# KM1M7CF15 register map
Vendor: Nuvoton Technology Corporation Japan; Series: KM1M7CF; File version: 1.0.3
CPU: CM7 r1p2, little endian, MPU, FPU, double-precision FPU, I-cache, D-cache, ITCM, DTCM, 4 interrupt priority bits
Registers are 32-bit, read-write, no defined reset value unless marked. A register's access mark holds for its fields unless they carry their own. Offsets are from the block's base; [hi:lo] are bit positions; 'fields as' and 'values as' point back to an identical list.

## SIF01 — Serial Interface 0-1
Base 0x40050000
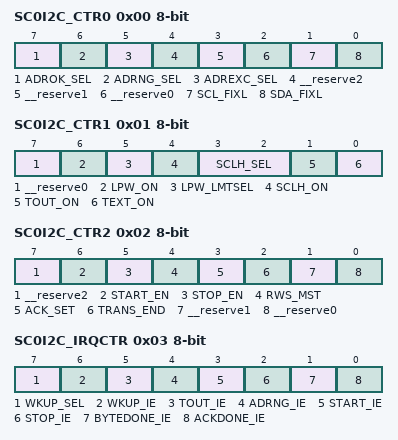
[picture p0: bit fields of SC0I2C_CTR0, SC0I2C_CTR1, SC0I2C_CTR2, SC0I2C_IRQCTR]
0x00 SC0I2C_CTR0 8-bit access per field — IIC Co0trol Register 0
  [7] ADROK_SEL rw — Slave address receive mode selection [IIC] (*1)(*3)
  [6] ADRNG_SEL rw — Slave address receive mode selection [IIC] (*1)(*3)
  [5] ADREXC_SEL rw — Extension code matching operation select [IIC] (*1)(*2)(*3)
  [4] __reserve2 ro — "0" is always read out.
  [3] __reserve1 rw — This bit must be set to "0".
  [2] __reserve0 ro — "0" is always read out.
  [1] SCL_FIXL rw — SCL port LOW level output [IIC] (*3)
  [0] SDA_FIXL rw — SDA port LOW level output [IIC] (*3)
0x01 SC0I2C_CTR1 8-bit access per field — IIC Co0trol Register 1
  [7] __reserve0 ro — "0" is always read out.
  [6] LPW_ON rw — Bus stop detection enable [IIC] (*1)
  [5] LPW_LMTSEL rw — Bus stop detection period [IIC] (*1)
  [4] SCLH_ON rw — Clock "High-level" period (THIGH) detection enable [IIC] (*1)
  [3:2] SCLH_SEL rw — Clock "High-level" period detection time [IIC] (*1)
  [1] TOUT_ON rw — Clock "Low-level" period (TTIMEOUT) detection enable [IIC] (*1)
  [0] TEXT_ON rw — TLOW:MEXT / TLOW:SEXT detection enable [IIC] (*1)
0x02 SC0I2C_CTR2 8-bit access per field — IIC Co0trol Register 2
  [7] __reserve2 ro — "0" is always read out.
  [6] START_EN rw — Start condition generation selection [IIC] (*1)(*4)
  [5] STOP_EN rw — Stop condition generation selection [IIC Master communication] (*2)(*4)
  [4] RWS_MST rw — Read/Write mode selection at Master [IIC] (*3)(*4)
  [3] ACK_SET rw — Transmission ACK bit selection [IIC] (*4)
  [2] TRANS_END rw — Communication end setting (*4)
  [1] __reserve1 ro — "0" is always read out.
  [0] __reserve0 ro — "0" is always read out.
0x03 SC0I2C_IRQCTR 8-bit — IIC I0terrupt Control Register
  [7] WKUP_SEL — Interrupt source selection for exiting CPU standby mode [IIC] (*5)
  [6] WKUP_IE — Enable CPU WAKEUP interrupt factor [IIC] (*1)(*5)
  [5] TOUT_IE — Enable Time-out interrupt factor [IIC] (*5)
  [4] ADRNG_IE — Enable Slave address mismatch interrupt factor [IIC] (*5)
  [3] START_IE — Enable Start condition detection interrupt factor [IIC] (*5)
  [2] STOP_IE — Enable Stop condition interrupt factor [IIC] (*5)
  [1] BYTEDONE_IE — Enable Byte data communication completion interrupt factor [IIC] (*2)(*3)(*5)
  [0] ACKDONE_IE — Enable ACK communication completion interrupt factor [IIC] (*4)(*5)
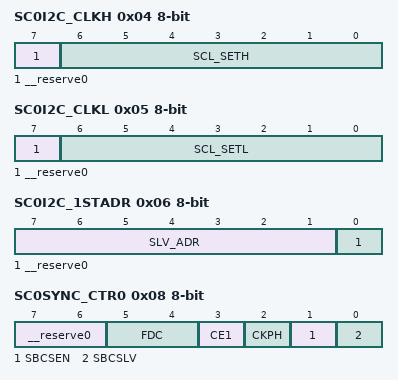
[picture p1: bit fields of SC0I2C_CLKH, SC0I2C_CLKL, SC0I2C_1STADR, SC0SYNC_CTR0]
0x04 SC0I2C_CLKH 8-bit access per field — IIC Clock High Level Freque0cy Setting Register
  [7] __reserve0 ro — "0" is always read out.
  [6:0] SCL_SETH rw — High level period of transfer clock at master communication [IIC] (*1)(*2)(*3)
0x05 SC0I2C_CLKL 8-bit access per field — IIC Clock Low Level Freque0cy Setting Register
  [7] __reserve0 ro — "0" is always read out.
  [6:0] SCL_SETL rw — Low level period of transfer clock at master communication [IIC] (*1)(*2)(*3)
0x06 SC0I2C_1STADR 8-bit access per field — IIC Slave Address Setti0g Register
  [7:1] SLV_ADR rw — Set the slave address. [IIC] (*1)(*2)
  [0] __reserve0 ro — "0" is always read out.
0x07 SC0I2C_TCLKOC 8-bit — IIC Timeout Clock Compare Register
  [7:0] TCLKOC — Time-out clock source division counter compare setting [IIC] (*1)(*2)
0x08 SC0SYNC_CTR0 8-bit access per field — Clock-Sy0chronous Control Register
  [7:6] __reserve0 ro — "0" is always read out.
  [5:4] FDC rw — Output level selection after the final bit transmit (SBOn pin) [Clock-Synchronous]
  [3] CE1 rw — Clock polarity selection (SCLn) [Clock-Synchronous]
  [2] CKPH rw — Clock Source Edge Selection [Clock-Synchronous]
  [1] SBCSEN rw — SBCSn function selection [Clock-Synchronous]
  [0] SBCSLV rw — SBCSn polarity selection [Clock-Synchronous]
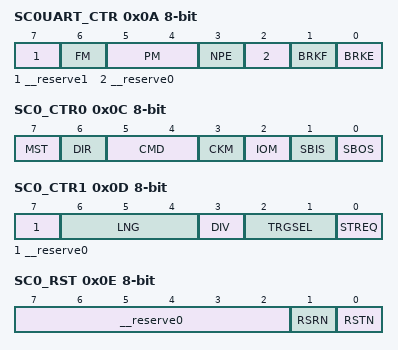
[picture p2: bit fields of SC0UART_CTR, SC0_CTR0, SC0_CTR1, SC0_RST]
0x0A SC0UART_CTR 8-bit access per field — UART Co0trol Register
  [7] __reserve1 ro — "0" is always read out.
  [6] FM rw — The number of character bit and stop bit selection [UART]
  [5:4] PM rw — Parity bit function selection [UART]
  [3] NPE rw — Parity bit selection [UART]
  [2] __reserve0 ro — "0" is always read out.
  [1] BRKF ro — Break reception detection [UART]
  [0] BRKE rw — Break transmission control [UART]
0x0C SC0_CTR0 8-bit — Serial 0 control register 0
  [7] MST — [Clock-Synchronous]
  [6] DIR — Transfer first bit selection
  [5:4] CMD — Communication mode selection (*1)
  [3] CKM — [Clock-Synchronous] Division selection of transfer clock
  [2] IOM — Data input pin selection (*2)
  [1] SBIS — SBIn/SBOn(SDAn) pin input control (*2)
  [0] SBOS — SBOn(SDAn) pin output control (*2)
0x0D SC0_CTR1 8-bit access per field — Serial 0 control register 1
  [7] __reserve0 ro — "0" is always read out.
  [6:4] LNG rw — Transfer bit count settings [Clock-Synchronous/UART]
  [3] DIV rw — Division value selection of transfer clock (*3)
  [2:1] TRGSEL rw — Selection of communication start factor(*1)
  [0] STREQ rw — Communication start trigger by software (*1)(*2)
0x0E SC0_RST 8-bit access per field — Serial 0 Reset Register
  [7:2] __reserve0 ro — "00" is always read out.
  [1] RSRN rw — [Clock-Synchronous]
  [0] RSTN rw — [Clock-Synchronous / IIC]
0x10 SC0RB 8-bit ro — Serial 0 Reception Data Buffer Register
  [7:0] RB — Reception data is read out.
0x12 SC0TB 8-bit — Serial 0 Transmission Data Buffer Register
  [7:0] TB — Set the transmission data or the dummy data.
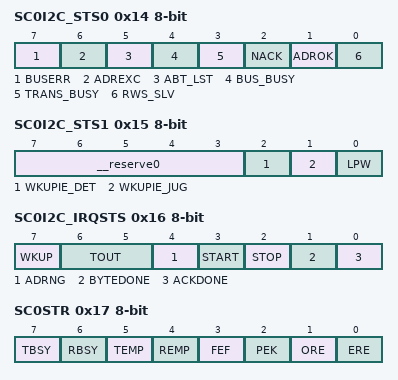
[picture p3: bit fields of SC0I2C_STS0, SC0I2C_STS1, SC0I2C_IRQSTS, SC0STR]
0x14 SC0I2C_STS0 8-bit access per field — IIC Status Register 0
  [7] BUSERR rw — Bus error detection [IIC] (*1)
  [6] ADREXC ro — Extension code receive detection [IIC]
  [5] ABT_LST rw — Arbitration lost detection [IIC] (*1)
  [4] BUS_BUSY ro — Bus busy state detection [IIC] (*2)
  [3] TRANS_BUSY ro — Communication busy state detection [IIC] (*3)
  [2] NACK ro — NACK detection [IIC]
  [1] ADROK ro — Slave address matching detection [IIC]
  [0] RWS_SLV ro — Read/ Write mode determination at Master/Slave communication [IIC] (*4)
0x15 SC0I2C_STS1 8-bit ro — IIC Status Register 1
  [7:3] __reserve0 — "0" is always read out.
  [2] WKUPIE_DET — CPU WAKEUP interrupt status [IIC]
  [1] WKUPIE_JUG — WKUP interrupt judgement [IIC]
  [0] LPW — Bus stop detection [IIC]
0x16 SC0I2C_IRQSTS 8-bit access per field — IIC I0terrupt Status Register
  [7] WKUP rw — IIC standby status exit detection [IIC] (*1)(*2)
  [6:5] TOUT ro — Time-out detection [IIC] (*2)
  [4] ADRNG rw — Slave address mismatch detection [IIC] (*1)(*2)
  [3] START rw — Start condition detection [IIC] (*1)(*2)(*3)
  [2] STOP rw — Stop condition detection [IIC] (*1)(*2)
  [1] BYTEDONE rw — Byte data communication completion detection [IIC] (*1)(*2)
  [0] ACKDONE rw — ACK communication completion detection (*1) [IIC] (*1)(*2)
0x17 SC0STR 8-bit access per field — Clock-Sy0chronous/UART Status Register
  [7] TBSY ro — Transmission busy detection [Clock-Synchronous/UART]
  [6] RBSY ro — Reception busy detection [Clock-Synchronous/UART]
  [5] TEMP ro — Transmission buffer empty [Clock-Synchronous/UART]
  [4] REMP ro — Reception buffer empty [Clock-Synchronous/UART]
  [3] FEF rw — Framing error detection [UART](*1)
  [2] PEK rw — Parity error detection [UART](*1)
  [1] ORE rw — Overrun error detection [Clock-Synchronous/UART](*1)
  [0] ERE ro — Reception error detection [Clock-Synchronous/UART]
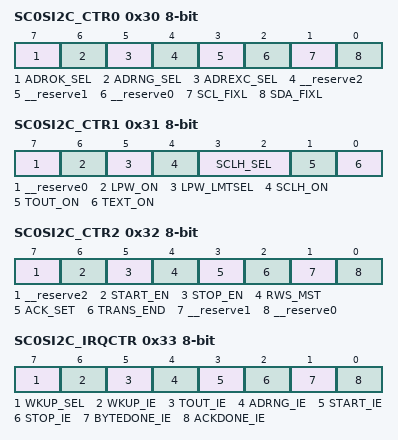
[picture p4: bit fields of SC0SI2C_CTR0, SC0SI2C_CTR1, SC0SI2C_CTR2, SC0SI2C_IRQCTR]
0x30 SC0SI2C_CTR0 8-bit wo — IIC Co0trol Set Register 0
  [7] ADROK_SEL — Set SCnI2C_CTR0.ADROK_SEL bit to "1"
  [6] ADRNG_SEL — Set SCnI2C_CTR0.ADRNG_SEL bit to "1"
  [5] ADREXC_SEL — Set SCnI2C_CTR0.ADREXC_SEL bit to "1"
  [4] __reserve2 — This bit must be set to "0".
  [3] __reserve1 — This bit must be set to "0".
  [2] __reserve0 — This bit must be set to "0".
  [1] SCL_FIXL — Set SCnI2C_CTR0.SCL_FIXL bit to "1"
  [0] SDA_FIXL — Set SCnI2C_CTR0.SDA_FIXL bit to "1"
0x31 SC0SI2C_CTR1 8-bit wo — IIC Co0trol Set Register 1
  [7] __reserve0 — This bit must be set to "0".
  [6] LPW_ON — Set SCnI2C_CTR1.LPW_ONL bit to "1"
  [5] LPW_LMTSEL — Set SCnI2C_CTR1.LPW_LMTSEL bit to "1"
  [4] SCLH_ON — Set SCnI2C_CTR1.SCLH_ON bit to "1"
  [3:2] SCLH_SEL — Set SCnI2C_CTR1.SCLH_SEL bit to "1"
  [1] TOUT_ON — Set SCnI2C_CTR1.TOUT_ON bit to "1"
  [0] TEXT_ON — Set SCnI2C_CTR1.TEXT_ON bit to "1"
0x32 SC0SI2C_CTR2 8-bit wo — IIC Co0trol Set Register 2
  [7] __reserve2 — This bit must be set to "0".
  [6] START_EN — Set SCnI2C_CTR2.START_EN bit to "1".
  [5] STOP_EN — Set SCnI2C_CTR2.STOP_EN bit to "1".
  [4] RWS_MST — Set SCnI2C_CTR2.RWS_MST bit to "1".
  [3] ACK_SET — Set SCnI2C_CTR2.ACK_SET bit to "1".
  [2] TRANS_END — Set SCnI2C_CTR2.TRANS_END bit to "1".
  [1] __reserve1 — This bit must be set to "0".
  [0] __reserve0 — This bit must be set to "0".
0x33 SC0SI2C_IRQCTR 8-bit wo — IIC I0terrupt Control Set Register
  [7] WKUP_SEL — Set SCnI2C_IRQCTR.WKUP_SEL bit to "1".
  [6] WKUP_IE — Set SCnI2C_IRQCTR.WKUP_IE bit to "1".
  [5] TOUT_IE — Set SCnI2C_IRQCTR.TOUT_IE bit to "1".
  [4] ADRNG_IE — Set SCnI2C_IRQCTR.ADRNG_IE bit to "1".
  [3] START_IE — Set SCnI2C_IRQCTR.START_IE bit to "1".
  [2] STOP_IE — Set SCnI2C_IRQCTR.STOP_IE bit to "1".
  [1] BYTEDONE_IE — Set SCnI2C_IRQCTR.BYTEDONE_IE bit to "1".
  [0] ACKDONE_IE — Set SCnI2C_IRQCTR.ACKDONE_IE bit to "1".
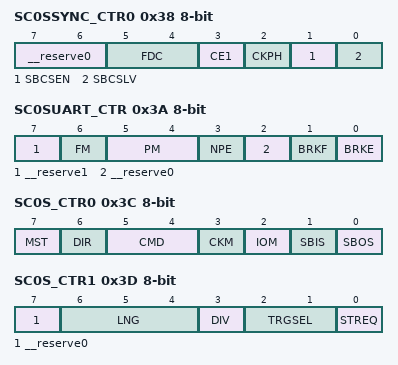
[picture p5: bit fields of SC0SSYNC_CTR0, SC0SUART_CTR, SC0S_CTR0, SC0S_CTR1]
0x38 SC0SSYNC_CTR0 8-bit wo — Clock-Sy0chronous Control Set Register
  [7:6] __reserve0 — This bit must be set to "0".
  [5:4] FDC — This bit must be set to "00".
  [3] CE1 — Set SCnSYNC_CTR0.CE1 bit to "1".
  [2] CKPH — Set SCnSYNC_CTR0.CKPH bit to "1".
  [1] SBCSEN — Set SCnSYNC_CTR0.SBCSEN bit to "1".
  [0] SBCSLV — Set SCnSYNC_CTR0.SBCSLV bit to "1".
0x3A SC0SUART_CTR 8-bit wo — UART Co0trol Set Register
  [7] __reserve1 — This bit must be set to "0".
  [6] FM — Set SCnUART_CTR.FM bit to "1"
  [5:4] PM — Set SCnUART_CTR.PM bit to "1"
  [3] NPE — Set SCnUART_CTR.NPE bit to "1"
  [2] __reserve0 — This bit must be set to "0".
  [1] BRKF — This bit must be set to "0".
  [0] BRKE — Set SCnUART_CTR.BRKE bit to "1"
0x3C SC0S_CTR0 8-bit wo — Serial 0 Control Set Register 0
  [7] MST — Set SCn_CTR0.MST bit to "1".
  [6] DIR — Set SCn_CTR0.DIR bit to "1".
  [5:4] CMD — This bit must be set to "00".
  [3] CKM — Set SCn_CTR0.CKM bit to "1".
  [2] IOM — Set SCn_CTR0.IOM bit to "1".
  [1] SBIS — Set SCn_CTR0.SBIS bit to "1".
  [0] SBOS — Set SCn_CTR0.SBOS bit to "1".
0x3D SC0S_CTR1 8-bit wo — Serial 0 Control Set Register 1
  [7] __reserve0 — This bit must be set to "0".
  [6:4] LNG — This bit must be set to "000".
  [3] DIV — Set SCn_CTR1.DIV bit to "1".
  [2:1] TRGSEL — This bit must be set to "00".
  [0] STREQ — Communication start trigger by software (*1)(*2)
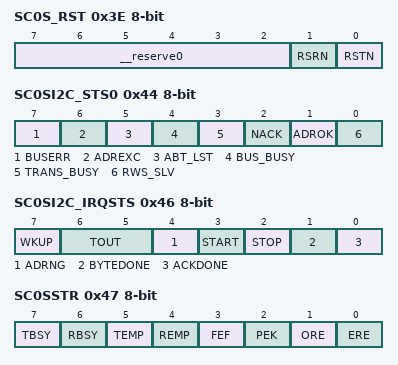
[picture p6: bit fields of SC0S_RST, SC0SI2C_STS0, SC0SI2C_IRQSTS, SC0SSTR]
0x3E SC0S_RST 8-bit wo — Serial 0 Reset Set Register
  [7:2] __reserve0 — This bit must be set to "00".
  [1] RSRN — Set SCn_RST.RSRN bit to "1"
  [0] RSTN — Set SCn_RST.RSTN bit to "1"
0x44 SC0SI2C_STS0 8-bit wo — IIC Status Set Register 0
  [7] BUSERR — Clear SCnI2C_STS0.BUSERR bit to "0".
  [6] ADREXC — This bit must be set to "0".
  [5] ABT_LST — Clear SCnI2C_STS0.ABT_LST bit to "0".
  [4] BUS_BUSY — This bit must be set to "0".
  [3] TRANS_BUSY — This bit must be set to "0".
  [2] NACK — This bit must be set to "0".
  [1] ADROK — This bit must be set to "0".
  [0] RWS_SLV — This bit must be set to "0".
0x46 SC0SI2C_IRQSTS 8-bit wo — IIC I0terrupt Clear Status Register
  [7] WKUP — Clear SCnI2C_IRQSTS.WKUP bit to "0".
  [6:5] TOUT — This bit must be set to "00".
  [4] ADRNG — Clear SCnI2C_IRQSTS.ADRNG bit to "0".
  [3] START — Clear C7I2C_IRQSTS.START bit to "0".
  [2] STOP — Clear SCnI2C_IRQSTS.STOP bit to "0".
  [1] BYTEDONE — Clear SCnI2C_IRQSTS.BYREDONE bit to "0".
  [0] ACKDONE — Clear SCnI2C_IRQSTS.ACKDONE bit to "0".
0x47 SC0SSTR 8-bit wo — Clock-Sy0chronous/UART Status Set Register
  [7] TBSY — This bit must be set to "0".
  [6] RBSY — This bit must be set to "0".
  [5] TEMP — This bit must be set to "0".
  [4] REMP — This bit must be set to "0".
  [3] FEF — Clear SCnSTR.FEF bit to "0". (*1)
  [2] PEK — Clear SCnSTR.PEK bit to "0". (*1)
  [1] ORE — Clear SCnSTR.ORE bit to "0". (*1)
  [0] ERE — This bit must be set to "0".
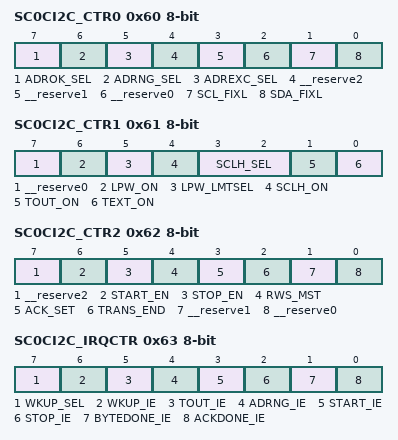
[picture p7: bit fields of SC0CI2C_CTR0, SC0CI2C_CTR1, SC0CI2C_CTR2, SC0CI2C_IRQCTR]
0x60 SC0CI2C_CTR0 8-bit wo — IIC Co0trol Clear Register 0
  [7] ADROK_SEL — Clear SCnI2C_CTR0.ADROK_SEL bit to "0"
  [6] ADRNG_SEL — Clear SCnI2C_CTR0.ADRNG_SEL bit to "0"
  [5] ADREXC_SEL — Clear SCnI2C_CTR0.ADREXC_SEL bit to "0"
  [4] __reserve2 — This bit must be set to "0".
  [3] __reserve1 — This bit must be set to "0".
  [2] __reserve0 — This bit must be set to "0".
  [1] SCL_FIXL — Clear SCnI2C_CTR0.SCL_FIXL bit to "0"
  [0] SDA_FIXL — Clear SCnI2C_CTR0.SDA_FIXL bit to "0"
0x61 SC0CI2C_CTR1 8-bit wo — IIC Co0trol Clear Register 1
  [7] __reserve0 — This bit must be set to "0".
  [6] LPW_ON — Clear SCnI2C_CTR1.LPW_ONL bit to "0"
  [5] LPW_LMTSEL — Clear SCnI2C_CTR1.LPW_LMTSEL bit to "0".
  [4] SCLH_ON — Clear SCnI2C_CTR1.SCLH_ON bit to "0".
  [3:2] SCLH_SEL — Clear SCnI2C_CTR1.SCLH_SEL bit to "0".
  [1] TOUT_ON — Clear SCnI2C_CTR1.TOUT_ON bit to "0".
  [0] TEXT_ON — Clear SCnI2C_CTR1.TEXT_ON bit to "0".
0x62 SC0CI2C_CTR2 8-bit wo — IIC Co0trol Clear Register 2
  [7] __reserve2 — This bit must be set to "0".
  [6] START_EN — Set SCnI2C_CTR2.START_EN bit to "0".
  [5] STOP_EN — Set SCnI2C_CTR2.STOP_EN bit to "0".
  [4] RWS_MST — Set SCnI2C_CTR2.RWS_MST bit to "0".
  [3] ACK_SET — Set SCnI2C_CTR2.ACK_SET bit to "0".
  [2] TRANS_END — Set SCnI2C_CTR2.TRANS_END bit to "0".
  [1] __reserve1 — This bit must be set to "0".
  [0] __reserve0 — This bit must be set to "0".
0x63 SC0CI2C_IRQCTR 8-bit wo — IIC I0terrupt Control Clear Register
  [7] WKUP_SEL — Clear SCnI2C_IRQCTR.WKUP_SEL bit to "0".
  [6] WKUP_IE — Clear SCnI2C_IRQCTR.WKUP_IE bit to "0".
  [5] TOUT_IE — Clear SCnI2C_IRQCTR.TOUT_IE bit to "0".
  [4] ADRNG_IE — Clear SCnI2C_IRQCTR.ADRNG_IE bit to "0".
  [3] START_IE — Clear SCnI2C_IRQCTR.START_IE bit to "0".
  [2] STOP_IE — Clear SCnI2C_IRQCTR.STOP_IE bit to "0".
  [1] BYTEDONE_IE — Clear SCnI2C_IRQCTR.BYTEDONE_IE bit to "0".
  [0] ACKDONE_IE — Clear SCnI2C_IRQCTR.ACKDONE_IE bit to "0".
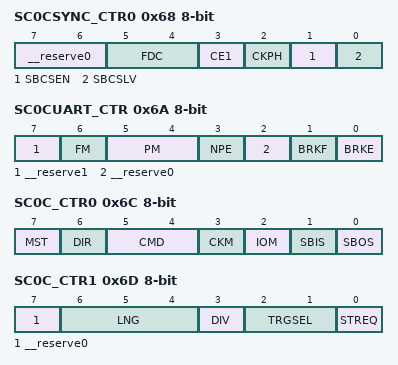
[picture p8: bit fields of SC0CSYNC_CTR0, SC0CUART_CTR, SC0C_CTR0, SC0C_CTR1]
0x68 SC0CSYNC_CTR0 8-bit wo — Clock-Sy0chronous Control Clear Register
  [7:6] __reserve0 — This bit must be set to "0".
  [5:4] FDC — This bit must be set to "00".
  [3] CE1 — Clear SCnSYNC_CTR0.CE1 bit to "0".
  [2] CKPH — Clear SCnSYNC_CTR0.CKPH bit to "0".
  [1] SBCSEN — Clear SCnSYNC_CTR0.SBCSEN bit to "0".
  [0] SBCSLV — Clear SCnSYNC_CTR0.SBCSLV bit to "0".
0x6A SC0CUART_CTR 8-bit wo — UART Co0trol Clear Register
  [7] __reserve1 — This bit must be set to "0".
  [6] FM — Clear SCnUART_CTR.FM bit to "0"
  [5:4] PM — Clear SCnUART_CTR.PM bit to "0"
  [3] NPE — Clear SCnUART_CTR.NPE bit to "0"
  [2] __reserve0 — This bit must be set to "0".
  [1] BRKF — This bit must be set to "0".
  [0] BRKE — Clear SCnUART_CTR.BRKE bit to "0"
0x6C SC0C_CTR0 8-bit wo — Serial 0 Control Clear Register 0
  [7] MST — Clear SCn_CTR0.MST bit to "0".
  [6] DIR — Clear SCn_CTR0.DIR bit to "0".
  [5:4] CMD — This bit must be set to "00".
  [3] CKM — Clear SCn_CTR0.CKM bit to "0".
  [2] IOM — Clear SCn_CTR0.IOM bit to "0".
  [1] SBIS — Clear SCn_CTR0.SBIS bit to "0".
  [0] SBOS — Clear SCn_CTR0.SBOS bit to "0".
0x6D SC0C_CTR1 8-bit wo — Serial 0 Control Clear Register 1
  [7] __reserve0 — This bit must be set to "0".
  [6:4] LNG — This bit must be set to "000".
  [3] DIV — Clear SCn_CTR1.DIV bit to "0".
  [2:1] TRGSEL — This bit must be set to "00".
  [0] STREQ — This bit must be set to "0".
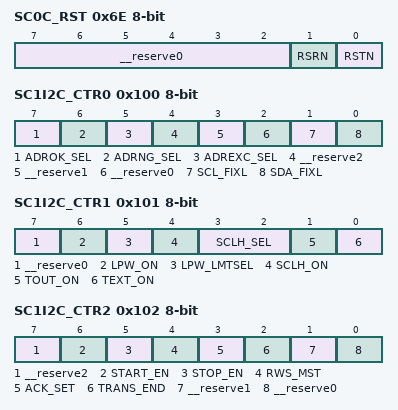
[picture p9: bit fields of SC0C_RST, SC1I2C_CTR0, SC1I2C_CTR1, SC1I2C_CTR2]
0x6E SC0C_RST 8-bit wo — Serial 0 Reset Clear Register
  [7:2] __reserve0 — This bit must be set to "0".
  [1] RSRN — Clear SCn_RST.RSRN bit to "0"
  [0] RSTN — Clear SCn_RST.RSTN bit to "0"
0x100 SC1I2C_CTR0 8-bit access per field — IIC Co1trol Register 0
  fields as SC0I2C_CTR0
0x101 SC1I2C_CTR1 8-bit access per field — IIC Co1trol Register 1
  fields as SC0I2C_CTR1
0x102 SC1I2C_CTR2 8-bit access per field — IIC Co1trol Register 2
  fields as SC0I2C_CTR2
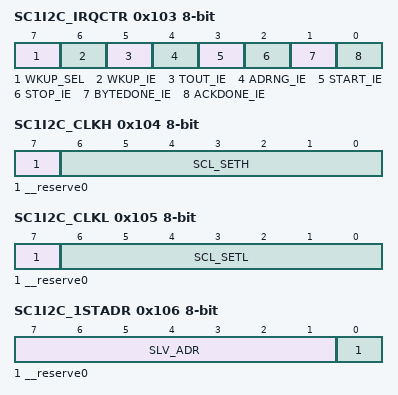
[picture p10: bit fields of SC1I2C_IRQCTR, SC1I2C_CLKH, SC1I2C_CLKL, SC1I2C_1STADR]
0x103 SC1I2C_IRQCTR 8-bit — IIC I1terrupt Control Register
  fields as SC0I2C_IRQCTR
0x104 SC1I2C_CLKH 8-bit access per field — IIC Clock High Level Freque1cy Setting Register
  fields as SC0I2C_CLKH
0x105 SC1I2C_CLKL 8-bit access per field — IIC Clock Low Level Freque1cy Setting Register
  fields as SC0I2C_CLKL
0x106 SC1I2C_1STADR 8-bit access per field — IIC Slave Address Setti1g Register
  fields as SC0I2C_1STADR
0x107 SC1I2C_TCLKOC 8-bit — IIC Timeout Clock Compare Register
  fields as SC0I2C_TCLKOC
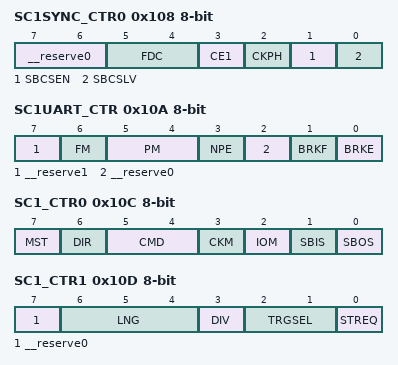
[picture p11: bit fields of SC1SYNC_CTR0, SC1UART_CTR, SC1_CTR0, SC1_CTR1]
0x108 SC1SYNC_CTR0 8-bit access per field — Clock-Sy1chronous Control Register
  fields as SC0SYNC_CTR0
0x10A SC1UART_CTR 8-bit access per field — UART Co1trol Register
  fields as SC0UART_CTR
0x10C SC1_CTR0 8-bit — Serial 1 control register 0
  fields as SC0_CTR0
0x10D SC1_CTR1 8-bit access per field — Serial 1 control register 1
  fields as SC0_CTR1
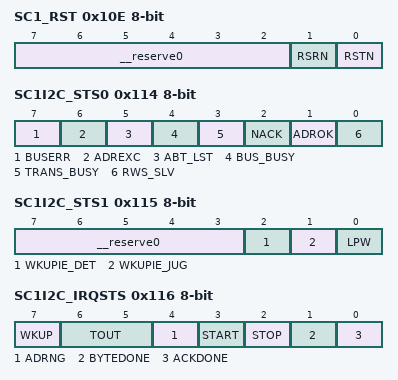
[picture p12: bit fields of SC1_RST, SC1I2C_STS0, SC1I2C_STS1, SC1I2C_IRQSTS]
0x10E SC1_RST 8-bit access per field — Serial 1 Reset Register
  fields as SC0_RST
0x110 SC1RB 8-bit ro — Serial 1 Reception Data Buffer Register
  [7:0] RB — Reception data is read out.
0x112 SC1TB 8-bit — Serial 1 Transmission Data Buffer Register
  [7:0] TB — Set the transmission data or the dummy data.
0x114 SC1I2C_STS0 8-bit access per field — IIC Status Register 0
  fields as SC0I2C_STS0
0x115 SC1I2C_STS1 8-bit ro — IIC Status Register 1
  fields as SC0I2C_STS1
0x116 SC1I2C_IRQSTS 8-bit access per field — IIC I1terrupt Status Register
  fields as SC0I2C_IRQSTS
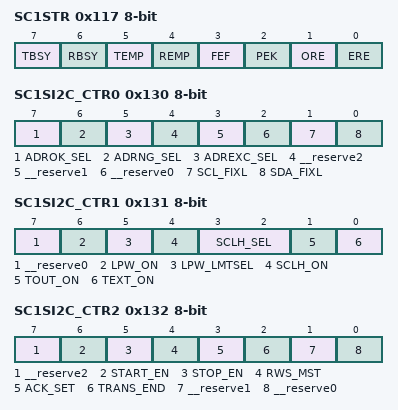
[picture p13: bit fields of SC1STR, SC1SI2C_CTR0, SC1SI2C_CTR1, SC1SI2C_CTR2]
0x117 SC1STR 8-bit access per field — Clock-Sy1chronous/UART Status Register
  fields as SC0STR
0x130 SC1SI2C_CTR0 8-bit wo — IIC Co1trol Set Register 0
  fields as SC0SI2C_CTR0
0x131 SC1SI2C_CTR1 8-bit wo — IIC Co1trol Set Register 1
  fields as SC0SI2C_CTR1
0x132 SC1SI2C_CTR2 8-bit wo — IIC Co1trol Set Register 2
  fields as SC0SI2C_CTR2
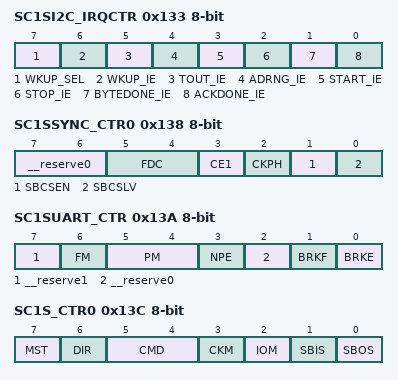
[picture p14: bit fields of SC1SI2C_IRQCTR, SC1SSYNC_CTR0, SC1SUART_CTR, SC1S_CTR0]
0x133 SC1SI2C_IRQCTR 8-bit wo — IIC I1terrupt Control Set Register
  fields as SC0SI2C_IRQCTR
0x138 SC1SSYNC_CTR0 8-bit wo — Clock-Sy1chronous Control Set Register
  fields as SC0SSYNC_CTR0
0x13A SC1SUART_CTR 8-bit wo — UART Co1trol Set Register
  fields as SC0SUART_CTR
0x13C SC1S_CTR0 8-bit wo — Serial 1 Control Set Register 0
  fields as SC0S_CTR0
0x13D SC1S_CTR1 8-bit wo — Serial 1 Control Set Register 1
  fields as SC0S_CTR1
0x13E SC1S_RST 8-bit wo — Serial 1 Reset Set Register
  fields as SC0S_RST
0x144 SC1SI2C_STS0 8-bit wo — IIC Status Set Register 0
  fields as SC0SI2C_STS0
0x146 SC1SI2C_IRQSTS 8-bit wo — IIC I1terrupt Clear Status Register
  fields as SC0SI2C_IRQSTS
0x147 SC1SSTR 8-bit wo — Clock-Sy1chronous/UART Status Set Register
  fields as SC0SSTR
0x160 SC1CI2C_CTR0 8-bit wo — IIC Co1trol Clear Register 0
  fields as SC0CI2C_CTR0
0x161 SC1CI2C_CTR1 8-bit wo — IIC Co1trol Clear Register 1
  fields as SC0CI2C_CTR1
0x162 SC1CI2C_CTR2 8-bit wo — IIC Co1trol Clear Register 2
  fields as SC0CI2C_CTR2
0x163 SC1CI2C_IRQCTR 8-bit wo — IIC I1terrupt Control Clear Register
  fields as SC0CI2C_IRQCTR
0x168 SC1CSYNC_CTR0 8-bit wo — Clock-Sy1chronous Control Clear Register
  fields as SC0CSYNC_CTR0
0x16A SC1CUART_CTR 8-bit wo — UART Co1trol Clear Register
  fields as SC0CUART_CTR
0x16C SC1C_CTR0 8-bit wo — Serial 1 Control Clear Register 0
  fields as SC0C_CTR0
0x16D SC1C_CTR1 8-bit wo — Serial 1 Control Clear Register 1
  fields as SC0C_CTR1
0x16E SC1C_RST 8-bit wo — Serial 1 Reset Clear Register
  fields as SC0C_RST
0xF04 BRTM_S01_CK 8-bit — Baud Rate Timer 01 Count Clock Selection Register
  [7:4] S1_CK — Selection of count clock in baud rate timer 1
  [3:0] S0_CK — Selection of count clock in baud rate timer 0
0xF10 BRTM_S0_OC 8-bit — Baud Rate Timer 0 Compare Register
  [7:0] Sn_OC — Set the value to be compared with the counter of baud rate timer.
0xF11 BRTM_S1_OC 8-bit — Baud Rate Timer 1 Compare Register
  fields as BRTM_S0_OC
